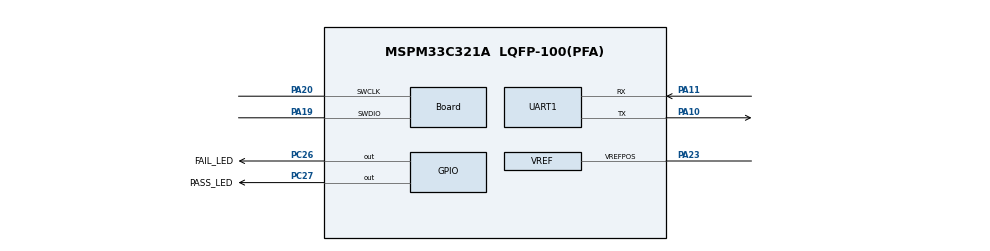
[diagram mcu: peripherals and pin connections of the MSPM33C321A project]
//@cliArgs --device "MSPM33C321A" --package "LQFP-100(PFA)" --part "Default"
//@v2CliArgs --device "MSPM33C321A" --package "LQFP-100(PFA)"
// @cliArgs --board /ti/boards/LP_MSPM33C321A --rtos nortos

/**
 * Import the modules used in this configuration.
 */
const GPIO          = scripting.addModule("/ti/driverlib/GPIO", {}, false);
const GPIO1         = GPIO.addInstance();
const HSADC         = scripting.addModule("/ti/driverlib/HSADC", {}, false);
const HSADC1        = HSADC.addInstance();
const SYSCTL        = scripting.addModule("/ti/driverlib/SYSCTL");
const UART          = scripting.addModule("/ti/driverlib/UART", {}, false);
const UART1         = UART.addInstance();
const VREF          = scripting.addModule("/ti/driverlib/VREF");
const ProjectConfig = scripting.addModule("/ti/project_config/ProjectConfig");

/**
 * Write custom configuration values to the imported modules.
 */
const multiplier2         = system.clockTree["PLL_QDIV"];
multiplier2.multiplyValue = 3;

GPIO1.$name                               = "GPIO_LEDS";
GPIO1.associatedPins.create(2);
GPIO1.associatedPins[0].$name             = "PASS_LED";
GPIO1.associatedPins[0].launchPadShortcut = "LED2GreenEn";
GPIO1.associatedPins[0].pin.$assign       = "PC27";
GPIO1.associatedPins[1].$name             = "FAIL_LED";
GPIO1.associatedPins[1].launchPadShortcut = "LED2RedEn";
GPIO1.associatedPins[1].pin.$assign       = "PC26";

const Board                       = scripting.addModule("/ti/driverlib/Board", {}, false);
Board.peripheral.$assign          = "DEBUGSS";
Board.peripheral.swclkPin.$assign = "PA20";
Board.peripheral.swdioPin.$assign = "PA19";

HSADC1.$name                      = "HSADC0";
HSADC1.seq1SampleWindow           = 16;
HSADC1.seq1Enable                 = true;
HSADC1.enableInterrupt1           = true;
HSADC1.ppb1AccumulationLimit      = "ADC_OVERSAMPLING_LIMIT_8";
HSADC1.seq2StartSOC               = "ADC_SOC_NUMBER1";
HSADC1.seq2Enable                 = true;
HSADC1.seq2SampleWindow           = 16;
HSADC1.interrupt2SOCSource        = "ADC_SOC_NUMBER1";
HSADC1.enableInterrupt2           = true;
HSADC1.enabledSOCs                = ["ADC_SOC_NUMBER0","ADC_SOC_NUMBER1","ADC_SOC_NUMBER2"];
HSADC1.enabledSEQs                = ["ADC_SEQ_NUMBER1","ADC_SEQ_NUMBER2","ADC_SEQ_NUMBER3"];
HSADC1.seqEndSOC                  = "ADC_SOC_NUMBER2";
HSADC1.seq3Enable                 = true;
HSADC1.seq3SampleWindow           = 16;
HSADC1.enabledInts                = ["ADC_INT_NUMBER_1","ADC_INT_NUMBER_2","ADC_INT_NUMBER_3"];
HSADC1.interrupt3SOCSource        = "ADC_SOC_NUMBER2";
HSADC1.enableInterrupt3           = true;
HSADC1.enabledPPBs                = ["ADC_PPB_NUMBER2","ADC_PPB_NUMBER3"];
HSADC1.ppb2AccumulationLimit      = "ADC_OVERSAMPLING_LIMIT_8";
HSADC1.ppb3AccumulationLimit      = "ADC_OVERSAMPLING_LIMIT_8";
HSADC1.ppb3Rightshift             = 3;
HSADC1.seq3StartSOC               = "ADC_SOC_NUMBER2";
HSADC1.ppb3CompSource             = "ADC_PPB_COMPSOURCE_SUM";
HSADC1.peripheral.$assign         = "ADC0";
HSADC1.peripheral.adcPin0.$assign = "PA27";

SYSCTL.clockTreeEn           = true;
SYSCTL.forceDefaultClkConfig = true;

UART1.$name                    = "UART_0";
UART1.targetBaudRate           = 115200;
UART1.enableFIFO               = true;
UART1.txFifoThreshold          = "DL_UART_TX_FIFO_LEVEL_EMPTY";
UART1.rxFifoThreshold          = "DL_UART_RX_FIFO_LEVEL_ONE_ENTRY";
UART1.peripheral.$assign       = "UC12";
UART1.peripheral.rxPin.$assign = "PA11";
UART1.peripheral.txPin.$assign = "PA10";
UART1.txPinConfig.$name        = "ti_driverlib_gpio_GPIOPinGeneric1";
UART1.txPinConfig.enableConfig = true;
UART1.rxPinConfig.$name        = "ti_driverlib_gpio_GPIOPinGeneric2";

VREF.peripheral.$assign            = "VREF";
VREF.peripheral.vrefPosPin.$assign = "PA23";
VREF.vrefPosPinConfig.$name        = "ti_driverlib_gpio_GPIOPinGeneric0";

ProjectConfig.migrationCondition = true;
